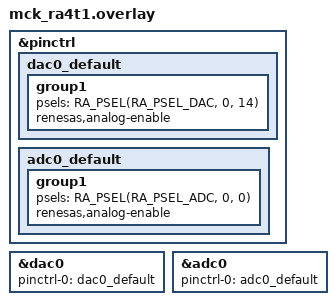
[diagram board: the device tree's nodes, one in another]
/*
 * Copyright (c) 2025 Renesas Electronics Corporation
 *
 * SPDX-License-Identifier: Apache-2.0
 */

&pinctrl {
	dac0_default: dac0_default {
		group1 {
			/* output */
			psels = <RA_PSEL(RA_PSEL_DAC, 0, 14)>;
			renesas,analog-enable;
		};
	};

	adc0_default: adc0_default {
		group1 {
			/* input */
			psels = <RA_PSEL(RA_PSEL_ADC, 0, 0)>;
			renesas,analog-enable;
		};
	};
};

&dac0 {
	pinctrl-0 = <&dac0_default>;
	pinctrl-names = "default";
	status = "okay";
};

&adc0 {
	pinctrl-0 = <&adc0_default>;
	pinctrl-names = "default";
	status = "okay";
};
